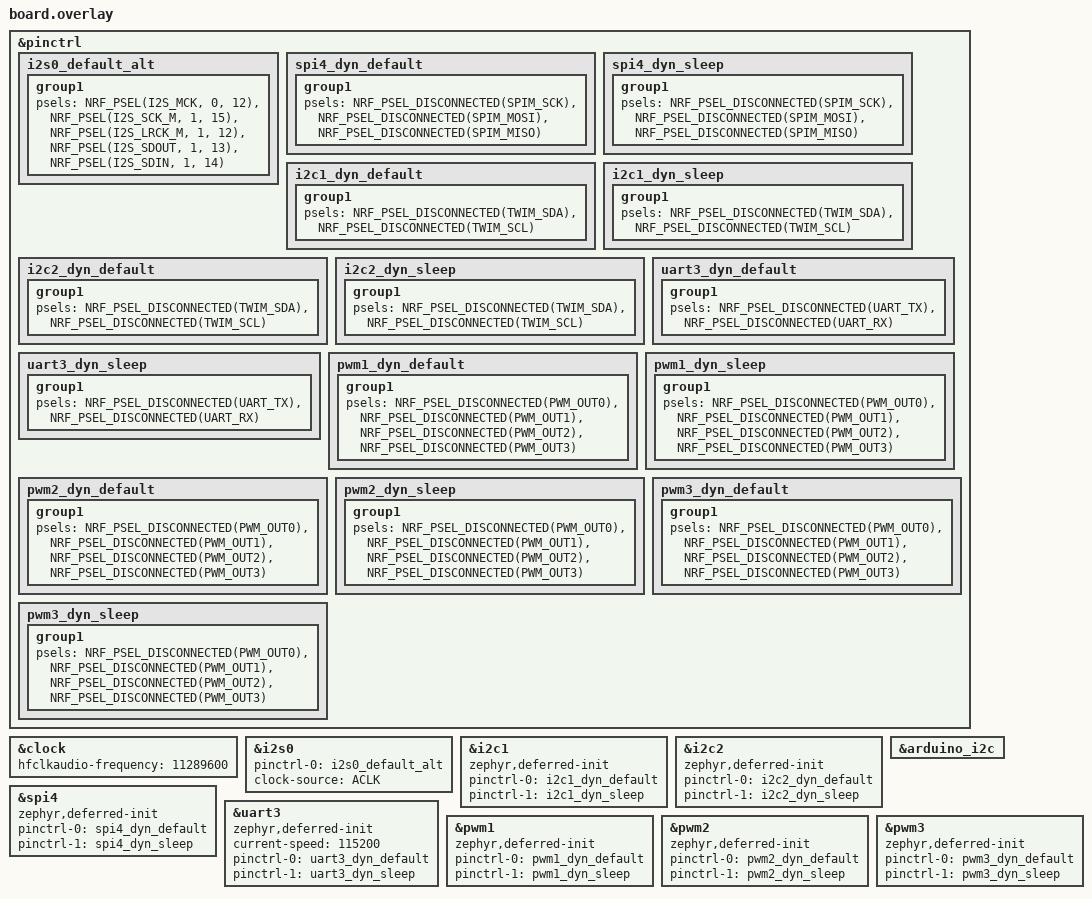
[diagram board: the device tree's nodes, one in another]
&pinctrl {
	i2s0_default_alt: i2s0_default_alt {
		group1 {
			psels = <NRF_PSEL(I2S_MCK, 0, 12)>,
				<NRF_PSEL(I2S_SCK_M, 1, 15)>,
				<NRF_PSEL(I2S_LRCK_M, 1, 12)>,
				<NRF_PSEL(I2S_SDOUT, 1, 13)>,
				<NRF_PSEL(I2S_SDIN, 1, 14)>;
		};
	};
};

&clock {
	hfclkaudio-frequency = <11289600>;
};

i2s_rxtx: &i2s0 {
	status = "okay";
	pinctrl-0 = <&i2s0_default_alt>;
	pinctrl-names = "default";
	clock-source = "ACLK";
};

// Enable free serial peripheral instances so CircuitPython can mux them to
// arbitrary pins at runtime. Each instance is enabled in one mode because the
// i2c/spi/uart nodes of an instance are the same peripheral (enforced by
// zephyr/soc/nordic/validate_enabled_instances.c). All signals are
// disconnected and the devices are marked zephyr,deferred-init so nothing is
// claimed at boot; iobroker initializes and routes a device when a busio
// object is constructed and de-initializes it on release.
//
// See "nRF serial instances" in internal-modules/iobroker/README.md for how
// the instances are shared and allocated.
//
// Instance 0 is left alone: uart0 is the console and i2c0/spi0 share that
// same peripheral, so they must not be enabled. Instance 1 is i2c1, the
// Arduino header I2C. spi4 is the upstream Arduino header SPI and the only
// SPI instance.

&pinctrl {
	spi4_dyn_default: spi4_dyn_default {
		group1 {
			psels = <NRF_PSEL_DISCONNECTED(SPIM_SCK)>,
				<NRF_PSEL_DISCONNECTED(SPIM_MOSI)>,
				<NRF_PSEL_DISCONNECTED(SPIM_MISO)>;
		};
	};

	spi4_dyn_sleep: spi4_dyn_sleep {
		group1 {
			psels = <NRF_PSEL_DISCONNECTED(SPIM_SCK)>,
				<NRF_PSEL_DISCONNECTED(SPIM_MOSI)>,
				<NRF_PSEL_DISCONNECTED(SPIM_MISO)>;
		};
	};

	i2c1_dyn_default: i2c1_dyn_default {
		group1 {
			psels = <NRF_PSEL_DISCONNECTED(TWIM_SDA)>,
				<NRF_PSEL_DISCONNECTED(TWIM_SCL)>;
		};
	};

	i2c1_dyn_sleep: i2c1_dyn_sleep {
		group1 {
			psels = <NRF_PSEL_DISCONNECTED(TWIM_SDA)>,
				<NRF_PSEL_DISCONNECTED(TWIM_SCL)>;
		};
	};

	i2c2_dyn_default: i2c2_dyn_default {
		group1 {
			psels = <NRF_PSEL_DISCONNECTED(TWIM_SDA)>,
				<NRF_PSEL_DISCONNECTED(TWIM_SCL)>;
		};
	};

	i2c2_dyn_sleep: i2c2_dyn_sleep {
		group1 {
			psels = <NRF_PSEL_DISCONNECTED(TWIM_SDA)>,
				<NRF_PSEL_DISCONNECTED(TWIM_SCL)>;
		};
	};

	uart3_dyn_default: uart3_dyn_default {
		group1 {
			psels = <NRF_PSEL_DISCONNECTED(UART_TX)>,
				<NRF_PSEL_DISCONNECTED(UART_RX)>;
		};
	};

	uart3_dyn_sleep: uart3_dyn_sleep {
		group1 {
			psels = <NRF_PSEL_DISCONNECTED(UART_TX)>,
				<NRF_PSEL_DISCONNECTED(UART_RX)>;
		};
	};
};

&i2c1 {
	status = "okay";
	zephyr,deferred-init;
	pinctrl-0 = <&i2c1_dyn_default>;
	pinctrl-1 = <&i2c1_dyn_sleep>;
	pinctrl-names = "default", "sleep";
};

&i2c2 {
	status = "okay";
	zephyr,deferred-init;
	pinctrl-0 = <&i2c2_dyn_default>;
	pinctrl-1 = <&i2c2_dyn_sleep>;
	pinctrl-names = "default", "sleep";
};

&spi4 {
	status = "okay";
	zephyr,deferred-init;
	pinctrl-0 = <&spi4_dyn_default>;
	pinctrl-1 = <&spi4_dyn_sleep>;
	pinctrl-names = "default", "sleep";
};

&uart3 {
	status = "okay";
	zephyr,deferred-init;
	current-speed = <115200>;
	pinctrl-0 = <&uart3_dyn_default>;
	pinctrl-1 = <&uart3_dyn_sleep>;
	pinctrl-names = "default", "sleep";
};

// board.I2C() is on the Arduino header SCL/SDA (D15/D14), and board.UART()
// on its TX/RX (D1/D0). uart1 is the upstream Arduino serial, but it is the
// same instance as i2c1, so board.UART() uses uart3 instead. There is no
// board.SPI(): the fixed i2s0 above uses the Arduino SPI pins. See
// BOARD_BUS_LABELS in cptools/zephyr2cp.py.
board_i2c: &arduino_i2c {};
board_serial: &uart3 {};

// PWM instances 1-3, same scheme: all four outputs disconnected and deferred
// init, so iobroker can hand an instance to neopixel_write and pwmio and
// route its outputs at runtime. Instance 0 is left as the board defines it:
// enabled with fixed pins for the PWM LED. nRF5340 has no power-domain pin
// restrictions, so any instance can drive any pad.

&pinctrl {
	pwm1_dyn_default: pwm1_dyn_default {
		group1 {
			psels = <NRF_PSEL_DISCONNECTED(PWM_OUT0)>,
				<NRF_PSEL_DISCONNECTED(PWM_OUT1)>,
				<NRF_PSEL_DISCONNECTED(PWM_OUT2)>,
				<NRF_PSEL_DISCONNECTED(PWM_OUT3)>;
		};
	};

	pwm1_dyn_sleep: pwm1_dyn_sleep {
		group1 {
			psels = <NRF_PSEL_DISCONNECTED(PWM_OUT0)>,
				<NRF_PSEL_DISCONNECTED(PWM_OUT1)>,
				<NRF_PSEL_DISCONNECTED(PWM_OUT2)>,
				<NRF_PSEL_DISCONNECTED(PWM_OUT3)>;
		};
	};

	pwm2_dyn_default: pwm2_dyn_default {
		group1 {
			psels = <NRF_PSEL_DISCONNECTED(PWM_OUT0)>,
				<NRF_PSEL_DISCONNECTED(PWM_OUT1)>,
				<NRF_PSEL_DISCONNECTED(PWM_OUT2)>,
				<NRF_PSEL_DISCONNECTED(PWM_OUT3)>;
		};
	};

	pwm2_dyn_sleep: pwm2_dyn_sleep {
		group1 {
			psels = <NRF_PSEL_DISCONNECTED(PWM_OUT0)>,
				<NRF_PSEL_DISCONNECTED(PWM_OUT1)>,
				<NRF_PSEL_DISCONNECTED(PWM_OUT2)>,
				<NRF_PSEL_DISCONNECTED(PWM_OUT3)>;
		};
	};

	pwm3_dyn_default: pwm3_dyn_default {
		group1 {
			psels = <NRF_PSEL_DISCONNECTED(PWM_OUT0)>,
				<NRF_PSEL_DISCONNECTED(PWM_OUT1)>,
				<NRF_PSEL_DISCONNECTED(PWM_OUT2)>,
				<NRF_PSEL_DISCONNECTED(PWM_OUT3)>;
		};
	};

	pwm3_dyn_sleep: pwm3_dyn_sleep {
		group1 {
			psels = <NRF_PSEL_DISCONNECTED(PWM_OUT0)>,
				<NRF_PSEL_DISCONNECTED(PWM_OUT1)>,
				<NRF_PSEL_DISCONNECTED(PWM_OUT2)>,
				<NRF_PSEL_DISCONNECTED(PWM_OUT3)>;
		};
	};
};

&pwm1 {
	status = "okay";
	zephyr,deferred-init;
	pinctrl-0 = <&pwm1_dyn_default>;
	pinctrl-1 = <&pwm1_dyn_sleep>;
	pinctrl-names = "default", "sleep";
};

&pwm2 {
	status = "okay";
	zephyr,deferred-init;
	pinctrl-0 = <&pwm2_dyn_default>;
	pinctrl-1 = <&pwm2_dyn_sleep>;
	pinctrl-names = "default", "sleep";
};

&pwm3 {
	status = "okay";
	zephyr,deferred-init;
	pinctrl-0 = <&pwm3_dyn_default>;
	pinctrl-1 = <&pwm3_dyn_sleep>;
	pinctrl-names = "default", "sleep";
};

#include "../../../app.overlay"
